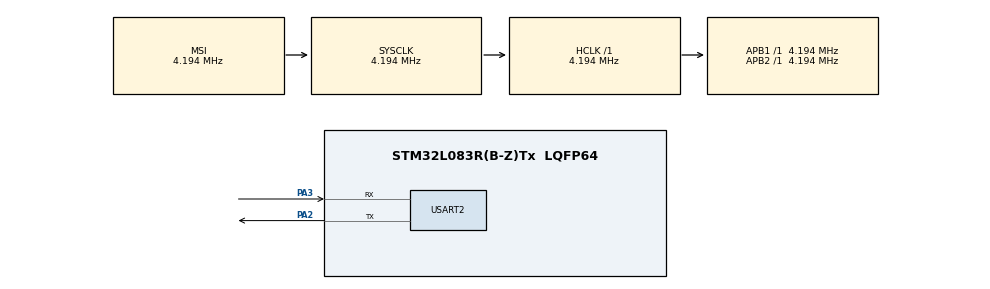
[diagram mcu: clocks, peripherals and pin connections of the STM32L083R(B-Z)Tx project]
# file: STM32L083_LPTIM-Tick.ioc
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FREERTOS.Tasks01=defaultTask,24,128,StartDefaultTask,Default,NULL,Dynamic,NULL,NULL
FREERTOS.configUSE_TICKLESS_IDLE=2
Mcu.Family=STM32L0
Mcu.Name=STM32L083R(B-Z)Tx
Mcu.Package=LQFP64
NVIC.TIM7_IRQn=true\:3\:0\:false\:false\:true\:false\:false\:true\:true
NVIC.TimeBase=TIM7_IRQn
NVIC.TimeBaseIP=TIM7
PA13.Mode=Serial_Wire
PA13.Signal=SYS_SWDIO
PA14.Mode=Serial_Wire
PA14.Signal=SYS_SWCLK
PA2.Mode=Asynchronous
PA2.Signal=USART2_TX
PA3.Mode=Asynchronous
PA3.Signal=USART2_RX
PC14-OSC32_IN.Mode=LSE-External-Oscillator
PC14-OSC32_IN.Signal=RCC_OSC32_IN
PC15-OSC32_OUT.Mode=LSE-External-Oscillator
PC15-OSC32_OUT.Signal=RCC_OSC32_OUT
PH0-OSC_IN.Mode=HSE-External-Oscillator
PH0-OSC_IN.Signal=RCC_OSC_IN
PH1-OSC_OUT.Mode=HSE-External-Oscillator
PH1-OSC_OUT.Signal=RCC_OSC_OUT
ProjectManager.HeapSize=0x200
ProjectManager.StackSize=0x400
ProjectManager.TargetToolchain=STM32CubeIDE
RCC.AHBFreq_Value=4194000
RCC.APB1Freq_Value=4194000
RCC.APB1TimFreq_Value=4194000
RCC.APB2Freq_Value=4194000
RCC.APB2TimFreq_Value=4194000
RCC.HCLKFreq_Value=4194000
RCC.HSE_VALUE=8000000
RCC.HSI16_VALUE=16000000
RCC.HSI48_VALUE=48000000
RCC.HSI_VALUE=16000000
RCC.MSIClockRange=RCC_MSIRANGE_6
RCC.MSI_VALUE=4194000
RCC.SYSCLKFreq_VALUE=4194000
RCC.VCOOutputFreq_Value=48000000
USART2.VirtualMode-Asynchronous=VM_ASYNC
VP_FREERTOS_VS_CMSIS_V2.Mode=CMSIS_V2
VP_RTC_VS_RTC_Activate.Mode=RTC_Enabled
VP_SYS_VS_tim7.Mode=TIM7
board=custom

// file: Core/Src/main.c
/* USER CODE BEGIN Header */
/**
  ******************************************************************************
  * @file           : main.c
  * @brief          : Main program body
  ******************************************************************************
  * @attention
  *
  * Copyright (c) 2026 STMicroelectronics.
  * All rights reserved.
  *
  * This software is licensed under terms that can be found in the LICENSE file
  * in the root directory of this software component.
  * If no LICENSE file comes with this software, it is provided AS-IS.
  *
  ******************************************************************************
  */
/* USER CODE END Header */
#include "main.h"

/* USER CODE BEGIN Includes */
#include "ulp.h"
/* USER CODE END Includes */

RTC_HandleTypeDef hrtc;

UART_HandleTypeDef huart2;

/* Definitions for defaultTask */

void SystemClock_Config(void);
static void MX_GPIO_Init(void);
static void MX_USART2_UART_Init(void);
static void MX_RTC_Init(void);

/* USER CODE BEGIN PFP */
void Task1(void *argument);
/* USER CODE END PFP */

int main(void)
{

  /* MCU Configuration--------------------------------------------------------*/

  /* Reset of all peripherals, Initializes the Flash interface and the Systick. */
  HAL_Init();

  /* Configure the system clock */
  SystemClock_Config();

  /* USER CODE BEGIN SysInit */
  vUlpInit();
  /* USER CODE END SysInit */

  /* Initialize all configured peripherals */
  MX_GPIO_Init();
  MX_USART2_UART_Init();
  MX_RTC_Init();

  /* Init scheduler */

  /* Create the thread(s) */
  /* creation of defaultTask */

  /* USER CODE BEGIN RTOS_THREADS */
  /* add threads, ... */
  xTaskCreate(Task1, "Task", 128, NULL, 1, NULL);
  /* USER CODE END RTOS_THREADS */

  /* USER CODE BEGIN RTOS_EVENTS */
  /* add events, ... */
  vTaskStartScheduler();
  /* USER CODE END RTOS_EVENTS */

  /* Start scheduler */
  /* We should never get here as control is now taken by the scheduler */

  /* Infinite loop */
  while (1)
  {

  }
}

void SystemClock_Config(void)
{
  RCC_OscInitTypeDef RCC_OscInitStruct = {0};
  RCC_ClkInitTypeDef RCC_ClkInitStruct = {0};
  RCC_PeriphCLKInitTypeDef PeriphClkInit = {0};

  /** Configure the main internal regulator output voltage
  */
  __HAL_PWR_VOLTAGESCALING_CONFIG(PWR_REGULATOR_VOLTAGE_SCALE1);

  /** Initializes the RCC Oscillators according to the specified parameters
  * in the RCC_OscInitTypeDef structure.
  */
  RCC_OscInitStruct.OscillatorType = RCC_OSCILLATORTYPE_LSI|RCC_OSCILLATORTYPE_MSI;
  RCC_OscInitStruct.LSIState = RCC_LSI_ON;
  RCC_OscInitStruct.MSIState = RCC_MSI_ON;
  RCC_OscInitStruct.MSICalibrationValue = 0;
  RCC_OscInitStruct.MSIClockRange = RCC_MSIRANGE_6;
  RCC_OscInitStruct.PLL.PLLState = RCC_PLL_NONE;
  if (HAL_RCC_OscConfig(&RCC_OscInitStruct) != HAL_OK)
  {
    Error_Handler();
  }

  /** Initializes the CPU, AHB and APB buses clocks
  */
  RCC_ClkInitStruct.ClockType = RCC_CLOCKTYPE_HCLK|RCC_CLOCKTYPE_SYSCLK
                              |RCC_CLOCKTYPE_PCLK1|RCC_CLOCKTYPE_PCLK2;
  RCC_ClkInitStruct.SYSCLKSource = RCC_SYSCLKSOURCE_MSI;
  RCC_ClkInitStruct.AHBCLKDivider = RCC_SYSCLK_DIV1;
  RCC_ClkInitStruct.APB1CLKDivider = RCC_HCLK_DIV1;
  RCC_ClkInitStruct.APB2CLKDivider = RCC_HCLK_DIV1;

  if (HAL_RCC_ClockConfig(&RCC_ClkInitStruct, FLASH_LATENCY_0) != HAL_OK)
  {
    Error_Handler();
  }
  PeriphClkInit.PeriphClockSelection = RCC_PERIPHCLK_USART2|RCC_PERIPHCLK_RTC;
  PeriphClkInit.Usart2ClockSelection = RCC_USART2CLKSOURCE_PCLK1;
  PeriphClkInit.RTCClockSelection = RCC_RTCCLKSOURCE_LSI;
  if (HAL_RCCEx_PeriphCLKConfig(&PeriphClkInit) != HAL_OK)
  {
    Error_Handler();
  }
}

static void MX_RTC_Init(void)
{

  /** Initialize RTC Only
  */
  hrtc.Instance = RTC;
  hrtc.Init.HourFormat = RTC_HOURFORMAT_24;
  hrtc.Init.AsynchPrediv = 127;
  hrtc.Init.SynchPrediv = 255;
  hrtc.Init.OutPut = RTC_OUTPUT_DISABLE;
  hrtc.Init.OutPutRemap = RTC_OUTPUT_REMAP_NONE;
  hrtc.Init.OutPutPolarity = RTC_OUTPUT_POLARITY_HIGH;
  hrtc.Init.OutPutType = RTC_OUTPUT_TYPE_OPENDRAIN;
  if (HAL_RTC_Init(&hrtc) != HAL_OK)
  {
    Error_Handler();
  }

}

static void MX_USART2_UART_Init(void)
{

  huart2.Instance = USART2;
  huart2.Init.BaudRate = 115200;
  huart2.Init.WordLength = UART_WORDLENGTH_8B;
  huart2.Init.StopBits = UART_STOPBITS_1;
  huart2.Init.Parity = UART_PARITY_NONE;
  huart2.Init.Mode = UART_MODE_TX_RX;
  huart2.Init.HwFlowCtl = UART_HWCONTROL_NONE;
  huart2.Init.OverSampling = UART_OVERSAMPLING_16;
  huart2.Init.OneBitSampling = UART_ONE_BIT_SAMPLE_DISABLE;
  huart2.AdvancedInit.AdvFeatureInit = UART_ADVFEATURE_NO_INIT;
  if (HAL_UART_Init(&huart2) != HAL_OK)
  {
    Error_Handler();
  }

}

static void MX_GPIO_Init(void)
{

  /* GPIO Ports Clock Enable */
  __HAL_RCC_GPIOC_CLK_ENABLE();
  __HAL_RCC_GPIOH_CLK_ENABLE();
  __HAL_RCC_GPIOA_CLK_ENABLE();

}

/* USER CODE BEGIN 4 */
void Task1(void *arguments)
{
	TIM7->CR1 &= ~TIM_CR1_CEN;  // wish CubeMX would generate a symbol for the HAL tick timer
	for(;;){
		  vTaskDelay(5000);
		  HAL_UART_Transmit(&huart2, (uint8_t *) "Hell0\n", 7, 100);
	}
}
/* USER CODE END 4 */

void HAL_TIM_PeriodElapsedCallback(TIM_HandleTypeDef *htim)
{
  if (htim->Instance == TIM7)
  {
    HAL_IncTick();
  }
}

void Error_Handler(void)
{
  __disable_irq();
  while (1)
  {
  }
}
